# ESP32-P4 register map
Vendor: ESPRESSIF SYSTEMS (SHANGHAI) CO., LTD.; Series: ESP32 P-Series; File version: 2
CPU: RV32IMAFC r0p0, little endian, no MPU, FPU, 0 interrupt priority bits
Address unit: 32 bits
Registers are 32-bit, read-write, reset 0x0 unless marked. A register's access mark holds for its fields unless they carry their own. Offsets are from the block's base; [hi:lo] are bit positions; {n}, {i} and the like mark numbered series.

## PCNT — Pulse Count Controller
Base 0x500C9000
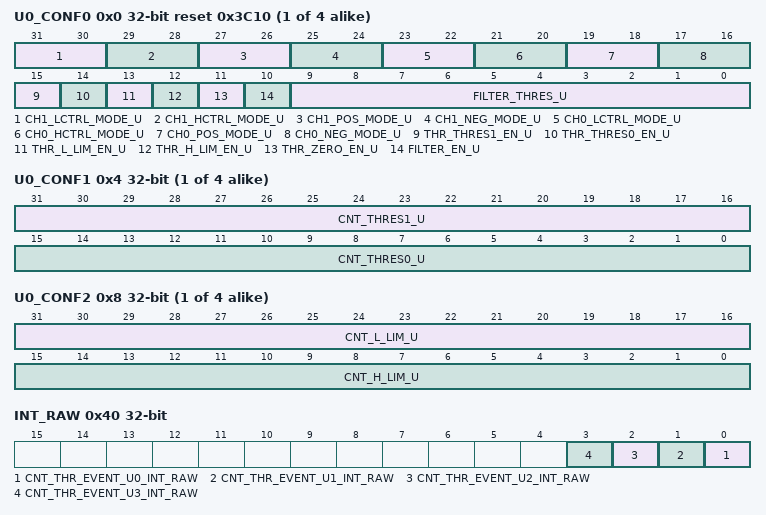
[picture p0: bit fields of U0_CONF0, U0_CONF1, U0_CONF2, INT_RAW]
{0x0+0xC*i} U{i}_CONF0 (i=0..3) reset 0x3C10 — Configuration register 0 for unit {i}
  [31:30] CH1_LCTRL_MODE_U — This register configures how the CH%s_POS_MODE/CH%s_NEG_MODE settings will be modified when the control signal is low. 0: No modification.1: Invert behavior (increase -> decrease, decrease -> increase).2, 3: Inhibit counter modification
  [29:28] CH1_HCTRL_MODE_U — This register configures how the CH%s_POS_MODE/CH%s_NEG_MODE settings will be modified when the control signal is high. 0: No modification.1: Invert behavior (increase -> decrease, decrease -> increase).2, 3: Inhibit counter modification
  [27:26] CH1_POS_MODE_U — This register sets the behavior when the signal input of channel 1 detects a positive edge. 1: Increment the counter.2: Decrement the counter.0, 3: No effect on counter
  [25:24] CH1_NEG_MODE_U — This register sets the behavior when the signal input of channel 1 detects a negative edge. 1: Increment the counter.2: Decrement the counter.0, 3: No effect on counter
  [23:22] CH0_LCTRL_MODE_U — This register configures how the CH%s_POS_MODE/CH%s_NEG_MODE settings will be modified when the control signal is low. 0: No modification.1: Invert behavior (increase -> decrease, decrease -> increase).2, 3: Inhibit counter modification
  [21:20] CH0_HCTRL_MODE_U — This register configures how the CH%s_POS_MODE/CH%s_NEG_MODE settings will be modified when the control signal is high. 0: No modification.1: Invert behavior (increase -> decrease, decrease -> increase).2, 3: Inhibit counter modification
  [19:18] CH0_POS_MODE_U — This register sets the behavior when the signal input of channel 0 detects a positive edge. 1: Increase the counter.2: Decrease the counter.0, 3: No effect on counter
  [17:16] CH0_NEG_MODE_U — This register sets the behavior when the signal input of channel 0 detects a negative edge. 1: Increase the counter.2: Decrease the counter.0, 3: No effect on counter
  [15] THR_THRES1_EN_U — This is the enable bit for unit %s's thres1 comparator.
  [14] THR_THRES0_EN_U — This is the enable bit for unit %s's thres0 comparator.
  [13] THR_L_LIM_EN_U — This is the enable bit for unit %s's thr_l_lim comparator. Configures it to enable the low limit interrupt.
  [12] THR_H_LIM_EN_U — This is the enable bit for unit %s's thr_h_lim comparator. Configures it to enable the high limit interrupt.
  [11] THR_ZERO_EN_U — This is the enable bit for unit %s's zero comparator.
  [10] FILTER_EN_U — This is the enable bit for unit %s's input filter.
  [9:0] FILTER_THRES_U — This sets the maximum threshold, in APB_CLK cycles, for the filter. Any pulses with width less than this will be ignored when the filter is enabled.
{0x4+0xC*i} U{i}_CONF1 (i=0..3) — Configuration register 1 for unit {i}
  [31:16] CNT_THRES1_U — This register is used to configure the thres1 value for unit %s.
  [15:0] CNT_THRES0_U — This register is used to configure the thres0 value for unit %s.
{0x8+0xC*i} U{i}_CONF2 (i=0..3) — Configuration register 2 for unit {i}
  [31:16] CNT_L_LIM_U — This register is used to configure the thr_l_lim value for unit %s. When pcnt reaches this value, the counter will be cleared to 0.
  [15:0] CNT_H_LIM_U — This register is used to configure the thr_h_lim value for unit %s. When pcnt reaches this value, the counter will be cleared to 0.
{0x30+4i} U{i}_CNT (i=0..3) ro — Counter value for unit {i}
  [15:0] PULSE_CNT_U — This register stores the current pulse count value for unit %s.
0x40 INT_RAW — Interrupt raw status register
  [n] CNT_THR_EVENT_U{n}_INT_RAW (n=0..3) — The raw interrupt status bit for the PCNT_CNT_THR_EVENT_U{n}_INT interrupt.
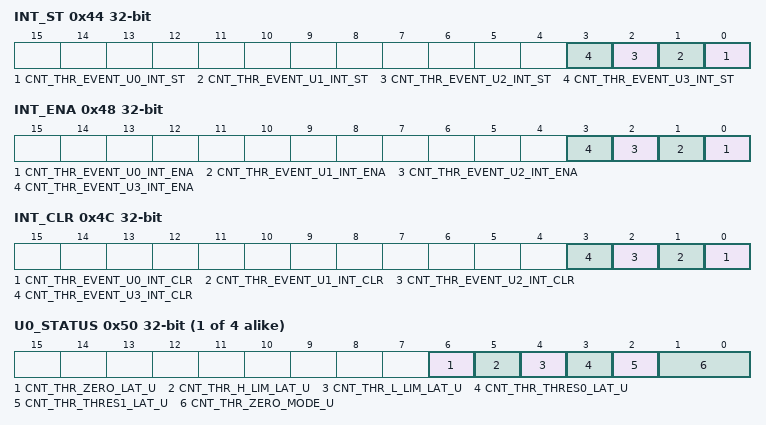
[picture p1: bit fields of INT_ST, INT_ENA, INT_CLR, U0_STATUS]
0x44 INT_ST ro — Interrupt status register
  [n] CNT_THR_EVENT_U{n}_INT_ST (n=0..3) — The masked interrupt status bit for the PCNT_CNT_THR_EVENT_U{n}_INT interrupt.
0x48 INT_ENA — Interrupt enable register
  [n] CNT_THR_EVENT_U{n}_INT_ENA (n=0..3) — The interrupt enable bit for the PCNT_CNT_THR_EVENT_U{n}_INT interrupt.
0x4C INT_CLR wo — Interrupt clear register
  [n] CNT_THR_EVENT_U{n}_INT_CLR (n=0..3) — Set this bit to clear the PCNT_CNT_THR_EVENT_U{n}_INT interrupt.
{0x50+4i} U{i}_STATUS (i=0..3) ro — PNCT UNIT{i} status register
  [6] CNT_THR_ZERO_LAT_U — The latched value of zero threshold event of PCNT_U%s when threshold event interrupt is valid. 1: the current pulse counter equals to 0 and zero threshold event is valid. 0: others
  [5] CNT_THR_H_LIM_LAT_U — The latched value of high limit event of PCNT_U%s when threshold event interrupt is valid. 1: the current pulse counter equals to thr_h_lim and high limit event is valid. 0: others
  [4] CNT_THR_L_LIM_LAT_U — The latched value of low limit event of PCNT_U%s when threshold event interrupt is valid. 1: the current pulse counter equals to thr_l_lim and low limit event is valid. 0: others
  [3] CNT_THR_THRES0_LAT_U — The latched value of thres0 event of PCNT_U%s when threshold event interrupt is valid. 1: the current pulse counter equals to thres0 and thres0 event is valid. 0: others
  [2] CNT_THR_THRES1_LAT_U — The latched value of thres1 event of PCNT_U%s when threshold event interrupt is valid. 1: the current pulse counter equals to thres1 and thres1 event is valid. 0: others
  [1:0] CNT_THR_ZERO_MODE_U — The pulse counter status of PCNT_U%s corresponding to 0. 0: pulse counter decreases from positive to 0. 1: pulse counter increases from negative to 0. 2: pulse counter is negative. 3: pulse counter is positive.
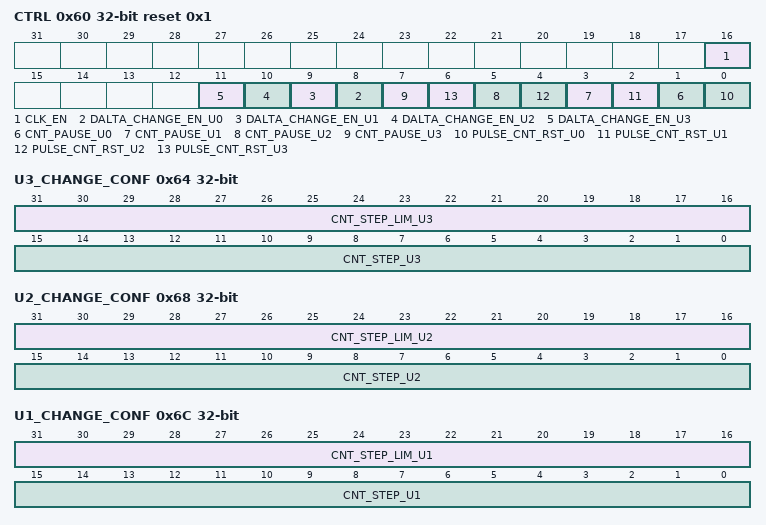
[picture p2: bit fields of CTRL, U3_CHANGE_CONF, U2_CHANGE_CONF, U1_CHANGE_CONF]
0x60 CTRL reset 0x1 — Control register for all counters
  [16] CLK_EN — The registers clock gate enable signal of PCNT module. 1: the registers can be read and written by application. 0: the registers can not be read or written by application
  [n+8] DALTA_CHANGE_EN_U{n} (n=0..3) — Configures this bit to enable unit {n}'s step comparator.
  [2n+1] CNT_PAUSE_U{n} (n=0..3) — Set this bit to freeze unit {n}'s counter.
  [2n] PULSE_CNT_RST_U{n} (n=0..3) — Set this bit to clear unit {n}'s counter.
0x64 U3_CHANGE_CONF — Configuration register for unit $n's step value.
  [31:16] CNT_STEP_LIM_U3 — Configures the step limit value for unit 3.
  [15:0] CNT_STEP_U3 — Configures the step value for unit 3.
0x68 U2_CHANGE_CONF — Configuration register for unit $n's step value.
  [31:16] CNT_STEP_LIM_U2 — Configures the step limit value for unit 2.
  [15:0] CNT_STEP_U2 — Configures the step value for unit 2.
0x6C U1_CHANGE_CONF — Configuration register for unit $n's step value.
  [31:16] CNT_STEP_LIM_U1 — Configures the step limit value for unit 1.
  [15:0] CNT_STEP_U1 — Configures the step value for unit 1.
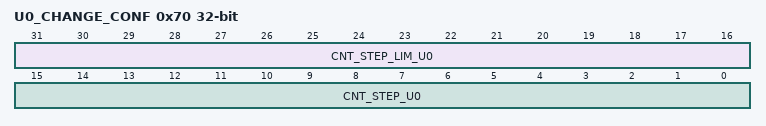
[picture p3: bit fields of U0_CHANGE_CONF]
0x70 U0_CHANGE_CONF — Configuration register for unit $n's step value.
  [31:16] CNT_STEP_LIM_U0 — Configures the step limit value for unit 0.
  [15:0] CNT_STEP_U0 — Configures the step value for unit 0.
0xFC DATE reset 0x22091900 — PCNT version control register
  [31:0] DATE — This is the PCNT version control register.
